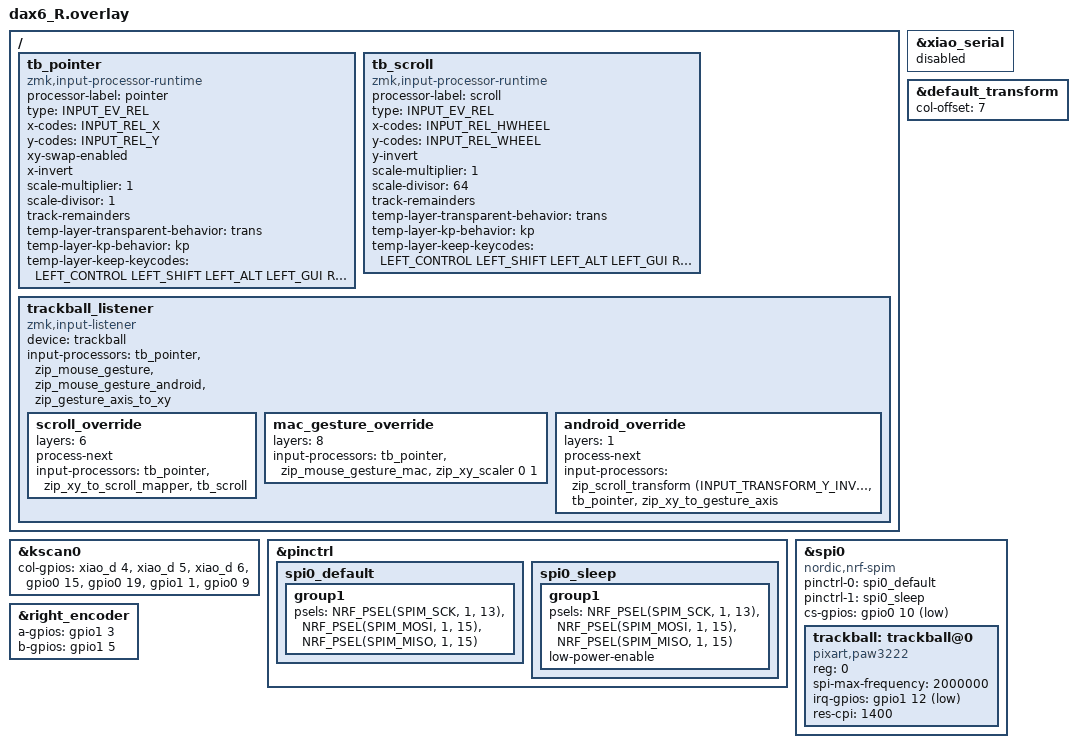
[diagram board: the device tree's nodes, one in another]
#include "dax6.dtsi"
#include <input/processors.dtsi>
#include <dt-bindings/zmk/input_transform.h>
#include <dt-bindings/zmk/keys.h>

&xiao_serial {
  status = "disabled";
};

&default_transform {
  col-offset = <7>;
};

&kscan0 {
  col-gpios
    = <&xiao_d 4 GPIO_ACTIVE_HIGH> // D4/P0.04 -> Col0
    , <&xiao_d 5 GPIO_ACTIVE_HIGH> // D5/P0.05 -> Col1
    , <&xiao_d 6 GPIO_ACTIVE_HIGH> // D6/P1.11 -> Col2
    , <&gpio0 15 GPIO_ACTIVE_HIGH> // P0.15 -> Col3
    , <&gpio0 19 GPIO_ACTIVE_HIGH> // P0.19 -> Col4
    , <&gpio1 1 GPIO_ACTIVE_HIGH>  // P1.01 -> Col5
    , <&gpio0 9 GPIO_ACTIVE_HIGH>  // GP 0.09 -> Col6
    ;
};

/ {
  // Runtime-tunable replacements for the fixed transform/scaler processors. The
  // properties are the compile-time defaults; values saved from a settings app
  // (custom Studio RPC, subsystem `cormoran_rip`) take precedence.
  //
  // `tb_pointer` owns the sensor orientation. The module inverts by the axis an
  // event had before the swap, so `xy-swap-enabled; x-invert;` is what
  // `zip_xy_transform (XY_SWAP | Y_INVERT)` used to do. It runs first in the
  // Scroll chain too, so its scale also multiplies scrolling.
  tb_pointer: tb_pointer {
    compatible = "zmk,input-processor-runtime";
    processor-label = "pointer";
    type = <INPUT_EV_REL>;
    x-codes = <INPUT_REL_X>;
    y-codes = <INPUT_REL_Y>;
    xy-swap-enabled;
    x-invert;
    scale-multiplier = <1>;
    scale-divisor = <1>;
    track-remainders;
    temp-layer-transparent-behavior = <&trans>;
    temp-layer-kp-behavior = <&kp>;
    temp-layer-keep-keycodes = <LEFT_CONTROL LEFT_SHIFT LEFT_ALT LEFT_GUI RIGHT_CONTROL RIGHT_SHIFT RIGHT_ALT RIGHT_GUI>;
    #input-processor-cells = <0>;
  };

  // Replaces `zip_scroll_transform (Y_INVERT)` + `zip_scroll_scaler 1 64` on the Scroll layer.
  tb_scroll: tb_scroll {
    compatible = "zmk,input-processor-runtime";
    processor-label = "scroll";
    type = <INPUT_EV_REL>;
    x-codes = <INPUT_REL_HWHEEL>;
    y-codes = <INPUT_REL_WHEEL>;
    y-invert;
    scale-multiplier = <1>;
    scale-divisor = <64>;
    track-remainders;
    temp-layer-transparent-behavior = <&trans>;
    temp-layer-kp-behavior = <&kp>;
    temp-layer-keep-keycodes = <LEFT_CONTROL LEFT_SHIFT LEFT_ALT LEFT_GUI RIGHT_CONTROL RIGHT_SHIFT RIGHT_ALT RIGHT_GUI>;
    #input-processor-cells = <0>;
  };

  trackball_listener {
    compatible = "zmk,input-listener";
    device = <&trackball>;
    // Both gesture processors live here because only the base chain propagates
    // ZMK_INPUT_PROC_STOP, which is what `suppress-movement` relies on. They never
    // collide: the macOS node reads X/Y, the Android node reads RX/RY, and each one
    // ignores codes it was not configured for. The trailing mapper turns the Android
    // chain's RX/RY back into X/Y so the listener can report them.
    input-processors
      = <&tb_pointer>
      , <&zip_mouse_gesture>
      , <&zip_mouse_gesture_android>
      , <&zip_gesture_axis_to_xy>
      ;

    scroll_override {
      layers = <6>;  // SCROLL layer
      process-next;
      input-processors
        = <&tb_pointer>
        , <&zip_xy_to_scroll_mapper>
        , <&tb_scroll>
        ;
    };

    mac_gesture_override {
      layers = <8>;  // MAC_GESTURE layer
      input-processors
        = <&tb_pointer>
        , <&zip_mouse_gesture_mac>
        , <&zip_xy_scaler 0 1>
        ;
    };

    // Declared last so the Scroll and MacGesture overrides win when their layer is
    // held; the Android layer is permanently active and would otherwise swallow them.
    // `process-next` hands the event to the base chain, where the Android gesture
    // node can actually suppress movement.
    android_override {
      layers = <1>;  // ANDROID layer
      process-next;
      input-processors
        = <&zip_scroll_transform (INPUT_TRANSFORM_Y_INVERT)>
        , <&tb_pointer>
        , <&zip_xy_to_gesture_axis>
        ;
    };
  };
};

&pinctrl {
  spi0_default: spi0_default {
    group1 {
      psels = <NRF_PSEL(SPIM_SCK, 1, 13)>, // P1.13 (D8/SCLK)
        <NRF_PSEL(SPIM_MOSI, 1, 15)>,      // P1.15 (D10/SDIO)
        <NRF_PSEL(SPIM_MISO, 1, 15)>;      // P1.15 (D10/SDIO)
    };
  };

  spi0_sleep: spi0_sleep {
    group1 {
      psels = <NRF_PSEL(SPIM_SCK, 1, 13)>,
        <NRF_PSEL(SPIM_MOSI, 1, 15)>,
        <NRF_PSEL(SPIM_MISO, 1, 15)>;
      low-power-enable;
    };
  };
};

&spi0 {
  status = "okay";
  compatible = "nordic,nrf-spim";
  pinctrl-0 = <&spi0_default>;
  pinctrl-1 = <&spi0_sleep>;
  pinctrl-names = "default", "sleep";
  cs-gpios = <&gpio0 10 GPIO_ACTIVE_LOW>;  // P0.10 (CS)

  trackball: trackball@0 {
    status = "okay";
    compatible = "pixart,paw3222";
    reg = <0>;
    spi-max-frequency = <2000000>;
    irq-gpios = <&gpio1 12 (GPIO_ACTIVE_LOW | GPIO_PULL_UP)>;  // P1.12 (D7/MOTION)
    res-cpi = <1400>;
  };
};

&right_encoder {
  a-gpios = <&gpio1 3 (GPIO_ACTIVE_HIGH | GPIO_PULL_UP)>;  // P1.03/RE_A
  b-gpios = <&gpio1 5 (GPIO_ACTIVE_HIGH | GPIO_PULL_UP)>;  // P1.05/RE_B
  status = "okay";
};
